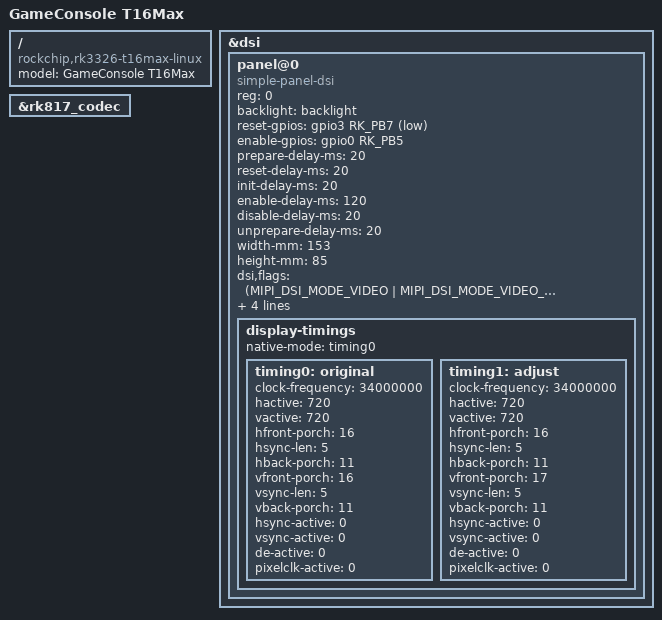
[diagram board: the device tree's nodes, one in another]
// SPDX-License-Identifier: (GPL-2.0+ OR MIT)
/*
* Copyright (c) 2025 kk&lcdyk
*
* GameConsole T16Max
*
*/

/dts-v1/;
#include "rk3326-r36max-type1-linux.dts"

/ {
	model = "GameConsole T16Max";
	compatible = "rockchip,rk3326-t16max-linux", "rockchip,rk3326";
};

&dsi {
	status = "okay";
	
	panel@0 {
		compatible = "simple-panel-dsi";
		reg = <0>;
		/* pwm1 backlight */
		backlight = <&backlight>;
		/* LCD reset gpio GPIO3.B7 */
		reset-gpios = <&gpio3 RK_PB7 GPIO_ACTIVE_LOW>;
		/* LCD reset gpio GPIO0.B5 */
		enable-gpios = <&gpio0 RK_PB5 GPIO_ACTIVE_HIGH>;
		prepare-delay-ms = <20>;
		reset-delay-ms = <20>;
		init-delay-ms = <20>;
		enable-delay-ms = <120>;
		disable-delay-ms = <20>;
		unprepare-delay-ms = <20>;
		width-mm = <153>;
		height-mm = <85>;
		dsi,flags  = <(MIPI_DSI_MODE_VIDEO |
		MIPI_DSI_MODE_VIDEO_BURST |
		MIPI_DSI_MODE_LPM |
		MIPI_DSI_MODE_EOT_PACKET)>;
		dsi,format = <MIPI_DSI_FMT_RGB888>;
		dsi,lanes = <4>;
		panel-init-sequence = <0x5c80111 0x5320129>;
		panel-exit-sequence = <0x5000128 0x5000110>;
		
		display-timings {
			native-mode = <&timing0>;

			// 34.00MHz / (720+16+5+11)×(720+16+5+11) = 752×752 = 60.12 Hz
			timing0: original {
				clock-frequency = <34000000>;
				hactive = <720>;
				vactive = <720>;
				hfront-porch = <16>;
				hsync-len = <5>;
				hback-porch = <11>;
				vfront-porch = <16>;
				vsync-len = <5>;
				vback-porch = <11>;
				hsync-active = <0>;
				vsync-active = <0>;
				de-active = <0>;
				pixelclk-active = <0>;
			};
			
			// 34.00MHz / (720+16+5+11)×(720+17+5+11) = 752×753 = 60.04 Hz
			timing1: adjust {
				clock-frequency = <34000000>;
				hactive = <720>;
				vactive = <720>;
				hfront-porch = <16>;
				hsync-len = <5>;
				hback-porch = <11>;
				vfront-porch = <17>;
				vsync-len = <5>;
				vback-porch = <11>;
				hsync-active = <0>;
				vsync-active = <0>;
				de-active = <0>;
				pixelclk-active = <0>;	
			};
		};
	};
};

&rk817_codec {
    /delete-property/ spk-ctl-gpios;
    /delete-property/ spk-mute-delay-ms;
    /delete-property/ use-ext-amplifier;
};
